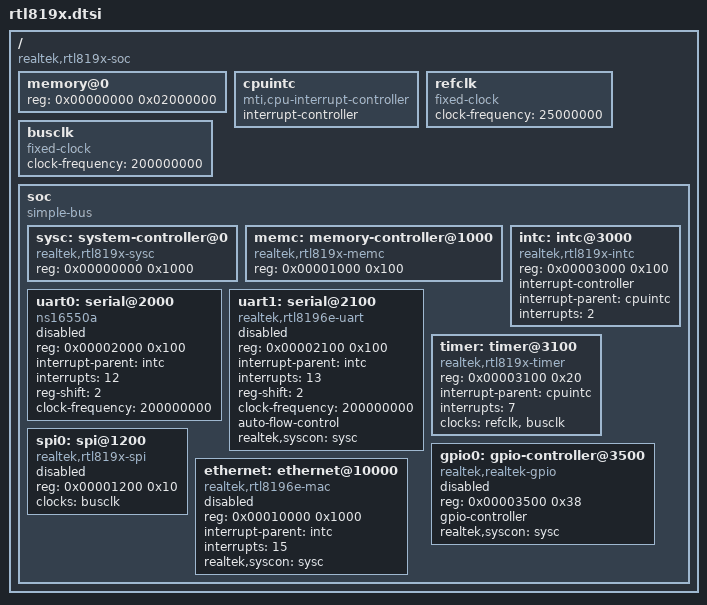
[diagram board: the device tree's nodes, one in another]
// SPDX-License-Identifier: GPL-2.0
/ {
	#address-cells = <1>;
	#size-cells = <1>;
	compatible = "realtek,rtl819x-soc";

	/*
	 * RTL8196E with 32 MiB DDR2
	 * Physical memory: 0x00000000 - 0x01FFFFFF
	 */
	memory@0 {
		device_type = "memory";
		reg = <0x00000000 0x02000000>;  /* 32 MiB */
	};

	cpuintc: cpuintc {
		#address-cells = <0>;
		#interrupt-cells = <1>;
		interrupt-controller;
		compatible = "mti,cpu-interrupt-controller";
	};

	refclk: refclk {
		#clock-cells = <0>;
		compatible = "fixed-clock";
		clock-frequency = <25000000>;
	};

	busclk: busclk {
		#clock-cells = <0>;
		compatible = "fixed-clock";
		clock-frequency = <200000000>;  /* LX bus clock: 200 MHz on RTL8196E */
	};

	soc {
		compatible = "simple-bus";
		#address-cells = <1>;
		#size-cells = <1>;
		
		/*
		 * Map 64 MiB window to access all peripherals including Switch
		 * This is address space mapping, NOT RAM consumption
		 */
		ranges = <0x00000000 0x18000000 0x04000000>;

		sysc: system-controller@0 {
			compatible = "realtek,rtl819x-sysc", "syscon";
			reg = <0x00000000 0x1000>;
		};

		memc: memory-controller@1000 {
			compatible = "realtek,rtl819x-memc";
			reg = <0x00001000 0x100>;
		};

		uart0: serial@2000 {
			compatible = "ns16550a";
			reg = <0x00002000 0x100>;
			interrupt-parent = <&intc>;
			interrupts = <12>;
			reg-shift = <2>;
			clock-frequency = <200000000>;
			status = "disabled";
		};

		uart1: serial@2100 {
			compatible = "realtek,rtl8196e-uart", "ns16550a";
			reg = <0x00002100 0x100>;
			interrupt-parent = <&intc>;
			interrupts = <13>;
			reg-shift = <2>;
			clock-frequency = <200000000>;
			/* Enable hardware flow control (RTS/CTS) for EFR32 Zigbee */
			auto-flow-control;
			realtek,syscon = <&sysc>;
			status = "disabled";
		};

		intc: intc@3000 {
			compatible = "realtek,rtl819x-intc";
			reg = <0x00003000 0x100>;
			interrupt-controller;
			#interrupt-cells = <1>;
			interrupt-parent = <&cpuintc>;
			interrupts = <2>;
		};

		timer: timer@3100 {
			compatible = "realtek,rtl819x-timer";
			reg = <0x00003100 0x20>;
			interrupt-parent = <&cpuintc>;
			interrupts = <7>;
			clocks = <&refclk>, <&busclk>;
			clock-names = "refclk", "busclk";
		};

		gpio0: gpio-controller@3500 {
			compatible = "realtek,realtek-gpio";
			reg = <0x00003500 0x38>;
			gpio-controller;
			#gpio-cells = <2>;
			realtek,syscon = <&sysc>;
			status = "disabled";
		};

		spi0: spi@1200 {
			compatible = "realtek,rtl819x-spi";
			reg = <0x00001200 0x10>;
			#address-cells = <1>;
			#size-cells = <0>;
			clocks = <&busclk>;
			status = "disabled";
		};

		ethernet: ethernet@10000 {
			compatible = "realtek,rtl8196e-mac";
			reg = <0x00010000 0x1000>;
			interrupt-parent = <&intc>;
			interrupts = <15>;
			realtek,syscon = <&sysc>;
			status = "disabled";
		};
	};
};
